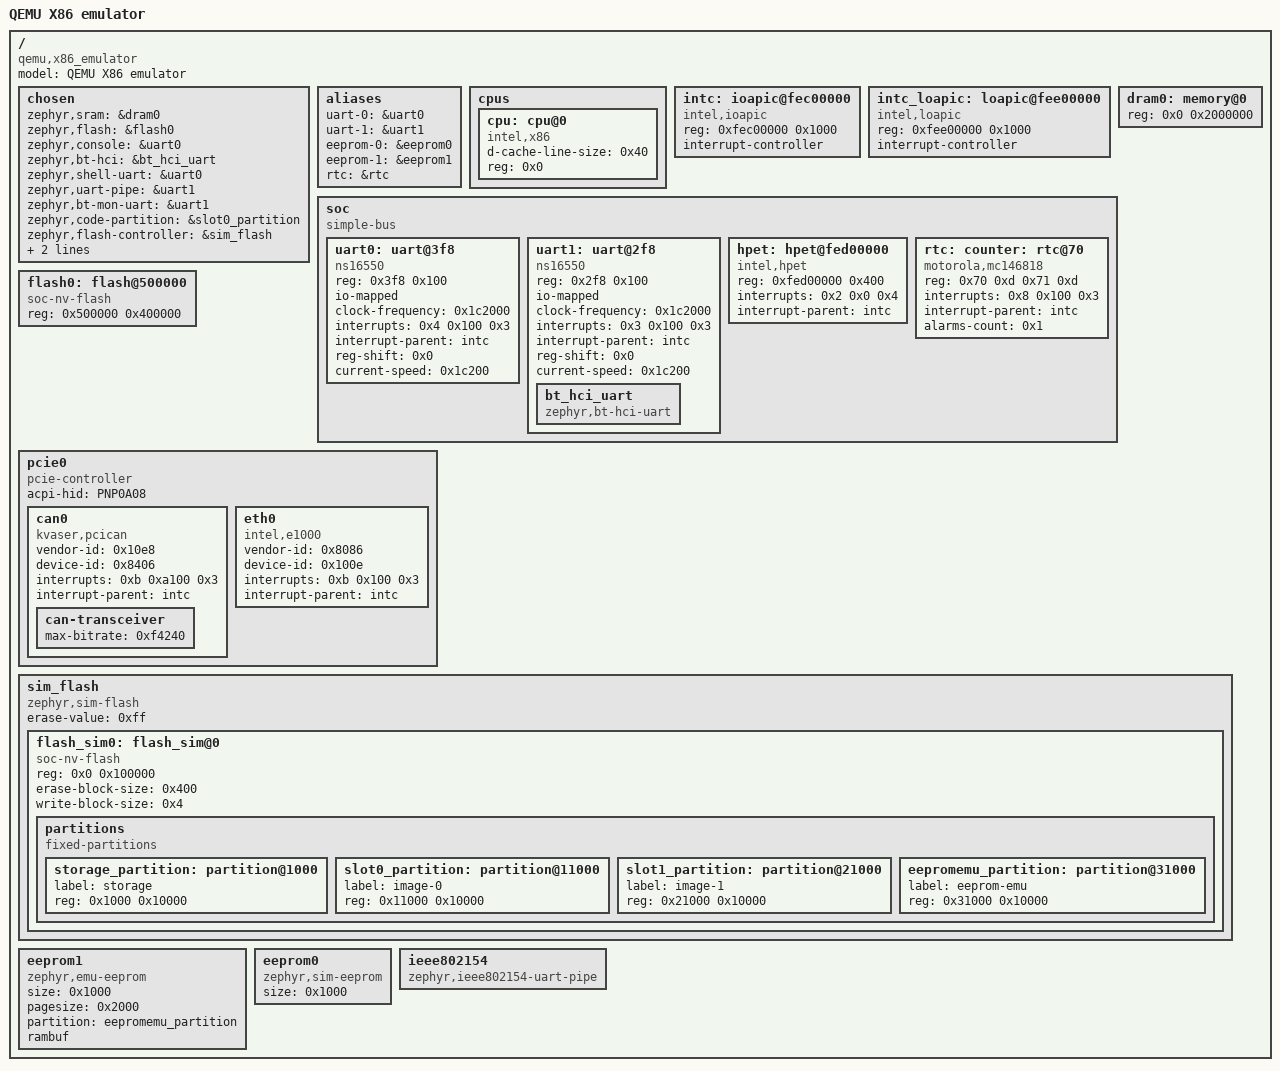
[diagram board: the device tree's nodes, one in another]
/dts-v1/;

/* node '/' defined in deps\zephyr\dts\common\skeleton.dtsi:9 */
/ {
	#address-cells = < 0x1 >;         /* in deps\zephyr\dts\common\skeleton.dtsi:10 */
	#size-cells = < 0x1 >;            /* in deps\zephyr\dts\common\skeleton.dtsi:11 */
	model = "QEMU X86 emulator";      /* in deps\zephyr\boards\qemu\x86\qemu_x86.dts:20 */
	compatible = "qemu,x86_emulator"; /* in deps\zephyr\boards\qemu\x86\qemu_x86.dts:21 */

	/* node '/chosen' defined in deps\zephyr\dts\common\skeleton.dtsi:12 */
	chosen {
		zephyr,sram = &dram0;                     /* in deps\zephyr\boards\qemu\x86\qemu_x86.dts:37 */
		zephyr,flash = &flash0;                   /* in deps\zephyr\boards\qemu\x86\qemu_x86.dts:38 */
		zephyr,console = &uart0;                  /* in deps\zephyr\boards\qemu\x86\qemu_x86.dts:39 */
		zephyr,bt-hci = &bt_hci_uart;             /* in deps\zephyr\boards\qemu\x86\qemu_x86.dts:40 */
		zephyr,shell-uart = &uart0;               /* in deps\zephyr\boards\qemu\x86\qemu_x86.dts:41 */
		zephyr,uart-pipe = &uart1;                /* in deps\zephyr\boards\qemu\x86\qemu_x86.dts:42 */
		zephyr,bt-mon-uart = &uart1;              /* in deps\zephyr\boards\qemu\x86\qemu_x86.dts:43 */
		zephyr,code-partition = &slot0_partition; /* in deps\zephyr\boards\qemu\x86\qemu_x86.dts:44 */
		zephyr,flash-controller = &sim_flash;     /* in deps\zephyr\boards\qemu\x86\qemu_x86.dts:45 */
		zephyr,ieee802154 = &ieee802154;          /* in deps\zephyr\boards\qemu\x86\qemu_x86.dts:46 */
		zephyr,canbus = &can0;                    /* in deps\zephyr\boards\qemu\x86\qemu_x86.dts:47 */
	};

	/* node '/aliases' defined in deps\zephyr\dts\common\skeleton.dtsi:13 */
	aliases {
		uart-0 = &uart0;     /* in deps\zephyr\boards\qemu\x86\qemu_x86.dts:29 */
		uart-1 = &uart1;     /* in deps\zephyr\boards\qemu\x86\qemu_x86.dts:30 */
		eeprom-0 = &eeprom0; /* in deps\zephyr\boards\qemu\x86\qemu_x86.dts:31 */
		eeprom-1 = &eeprom1; /* in deps\zephyr\boards\qemu\x86\qemu_x86.dts:32 */
		rtc = &rtc;          /* in deps\zephyr\boards\qemu\x86\qemu_x86.dts:33 */
	};

	/* node '/cpus' defined in deps\zephyr\dts\x86\intel\atom.dtsi:11 */
	cpus {
		#address-cells = < 0x1 >; /* in deps\zephyr\dts\x86\intel\atom.dtsi:12 */
		#size-cells = < 0x0 >;    /* in deps\zephyr\dts\x86\intel\atom.dtsi:13 */

		/* node '/cpus/cpu@0' defined in deps\zephyr\dts\x86\intel\atom.dtsi:15 */
		cpu: cpu@0 {
			device_type = "cpu";          /* in deps\zephyr\dts\x86\intel\atom.dtsi:16 */
			d-cache-line-size = < 0x40 >; /* in deps\zephyr\dts\x86\intel\atom.dtsi:17 */
			reg = < 0x0 >;                /* in deps\zephyr\dts\x86\intel\atom.dtsi:18 */
			compatible = "intel,x86";     /* in deps\zephyr\boards\qemu\x86\qemu_x86.dts:171 */
		};
	};

	/* node '/ioapic@fec00000' defined in deps\zephyr\dts\x86\intel\atom.dtsi:23 */
	intc: ioapic@fec00000 {
		compatible = "intel,ioapic"; /* in deps\zephyr\dts\x86\intel\atom.dtsi:24 */
		#address-cells = < 0x1 >;    /* in deps\zephyr\dts\x86\intel\atom.dtsi:25 */
		#interrupt-cells = < 0x3 >;  /* in deps\zephyr\dts\x86\intel\atom.dtsi:26 */
		reg = < 0xfec00000 0x1000 >; /* in deps\zephyr\dts\x86\intel\atom.dtsi:27 */
		interrupt-controller;        /* in deps\zephyr\dts\x86\intel\atom.dtsi:28 */
		phandle = < 0x1 >;           /* in deps\zephyr\dts\x86\intel\atom.dtsi:56 */
	};

	/* node '/loapic@fee00000' defined in deps\zephyr\dts\x86\intel\atom.dtsi:31 */
	intc_loapic: loapic@fee00000 {
		compatible = "intel,loapic"; /* in deps\zephyr\dts\x86\intel\atom.dtsi:32 */
		reg = < 0xfee00000 0x1000 >; /* in deps\zephyr\dts\x86\intel\atom.dtsi:33 */
		interrupt-controller;        /* in deps\zephyr\dts\x86\intel\atom.dtsi:34 */
		#interrupt-cells = < 0x3 >;  /* in deps\zephyr\dts\x86\intel\atom.dtsi:35 */
		#address-cells = < 0x1 >;    /* in deps\zephyr\dts\x86\intel\atom.dtsi:36 */
	};

	/* node '/memory@0' defined in deps\zephyr\dts\x86\intel\atom.dtsi:39 */
	dram0: memory@0 {
		device_type = "memory";  /* in deps\zephyr\dts\x86\intel\atom.dtsi:40 */
		reg = < 0x0 0x2000000 >; /* in deps\zephyr\dts\x86\intel\atom.dtsi:41 */
	};

	/* node '/soc' defined in deps\zephyr\dts\x86\intel\atom.dtsi:44 */
	soc {
		#address-cells = < 0x1 >;  /* in deps\zephyr\dts\x86\intel\atom.dtsi:45 */
		#size-cells = < 0x1 >;     /* in deps\zephyr\dts\x86\intel\atom.dtsi:46 */
		compatible = "simple-bus"; /* in deps\zephyr\dts\x86\intel\atom.dtsi:47 */
		ranges;                    /* in deps\zephyr\dts\x86\intel\atom.dtsi:48 */

		/* node '/soc/uart@3f8' defined in deps\zephyr\dts\x86\intel\atom.dtsi:50 */
		uart0: uart@3f8 {
			compatible = "ns16550";         /* in deps\zephyr\dts\x86\intel\atom.dtsi:51 */
			reg = < 0x3f8 0x100 >;          /* in deps\zephyr\dts\x86\intel\atom.dtsi:52 */
			io-mapped;                      /* in deps\zephyr\dts\x86\intel\atom.dtsi:53 */
			clock-frequency = < 0x1c2000 >; /* in deps\zephyr\dts\x86\intel\atom.dtsi:54 */
			interrupts = < 0x4 0x100 0x3 >; /* in deps\zephyr\dts\x86\intel\atom.dtsi:55 */
			interrupt-parent = < &intc >;   /* in deps\zephyr\dts\x86\intel\atom.dtsi:56 */
			reg-shift = < 0x0 >;            /* in deps\zephyr\dts\x86\intel\atom.dtsi:57 */
			status = "okay";                /* in deps\zephyr\boards\qemu\x86\qemu_x86.dts:121 */
			current-speed = < 0x1c200 >;    /* in deps\zephyr\boards\qemu\x86\qemu_x86.dts:122 */
		};

		/* node '/soc/uart@2f8' defined in deps\zephyr\dts\x86\intel\atom.dtsi:61 */
		uart1: uart@2f8 {
			compatible = "ns16550";         /* in deps\zephyr\dts\x86\intel\atom.dtsi:62 */
			reg = < 0x2f8 0x100 >;          /* in deps\zephyr\dts\x86\intel\atom.dtsi:63 */
			io-mapped;                      /* in deps\zephyr\dts\x86\intel\atom.dtsi:64 */
			clock-frequency = < 0x1c2000 >; /* in deps\zephyr\dts\x86\intel\atom.dtsi:65 */
			interrupts = < 0x3 0x100 0x3 >; /* in deps\zephyr\dts\x86\intel\atom.dtsi:66 */
			interrupt-parent = < &intc >;   /* in deps\zephyr\dts\x86\intel\atom.dtsi:67 */
			reg-shift = < 0x0 >;            /* in deps\zephyr\dts\x86\intel\atom.dtsi:68 */
			status = "okay";                /* in deps\zephyr\boards\qemu\x86\qemu_x86.dts:126 */
			current-speed = < 0x1c200 >;    /* in deps\zephyr\boards\qemu\x86\qemu_x86.dts:127 */

			/* node '/soc/uart@2f8/bt_hci_uart' defined in deps\zephyr\boards\qemu\x86\qemu_x86.dts:129 */
			bt_hci_uart: bt_hci_uart {
				compatible = "zephyr,bt-hci-uart"; /* in deps\zephyr\boards\qemu\x86\qemu_x86.dts:130 */
				status = "okay";                   /* in deps\zephyr\boards\qemu\x86\qemu_x86.dts:131 */
			};
		};

		/* node '/soc/hpet@fed00000' defined in deps\zephyr\dts\x86\intel\atom.dtsi:72 */
		hpet: hpet@fed00000 {
			compatible = "intel,hpet";    /* in deps\zephyr\dts\x86\intel\atom.dtsi:73 */
			reg = < 0xfed00000 0x400 >;   /* in deps\zephyr\dts\x86\intel\atom.dtsi:74 */
			interrupts = < 0x2 0x0 0x4 >; /* in deps\zephyr\dts\x86\intel\atom.dtsi:75 */
			interrupt-parent = < &intc >; /* in deps\zephyr\dts\x86\intel\atom.dtsi:76 */
			status = "okay";              /* in deps\zephyr\boards\qemu\x86\qemu_x86.dts:136 */
		};

		/* node '/soc/rtc@70' defined in deps\zephyr\dts\x86\intel\atom.dtsi:81 */
		rtc: counter: rtc@70 {
			compatible = "motorola,mc146818"; /* in deps\zephyr\dts\x86\intel\atom.dtsi:82 */
			reg = < 0x70 0xd 0x71 0xd >;      /* in deps\zephyr\dts\x86\intel\atom.dtsi:83 */
			interrupts = < 0x8 0x100 0x3 >;   /* in deps\zephyr\dts\x86\intel\atom.dtsi:84 */
			interrupt-parent = < &intc >;     /* in deps\zephyr\dts\x86\intel\atom.dtsi:85 */
			alarms-count = < 0x1 >;           /* in deps\zephyr\dts\x86\intel\atom.dtsi:86 */
			status = "okay";                  /* in deps\zephyr\dts\x86\intel\atom.dtsi:88 */
		};
	};

	/* node '/flash@500000' defined in deps\zephyr\boards\qemu\x86\qemu_x86.dts:23 */
	flash0: flash@500000 {
		compatible = "soc-nv-flash"; /* in deps\zephyr\boards\qemu\x86\qemu_x86.dts:24 */
		reg = < 0x500000 0x400000 >; /* in deps\zephyr\boards\qemu\x86\qemu_x86.dts:25 */
	};

	/* node '/pcie0' defined in deps\zephyr\boards\qemu\x86\qemu_x86.dts:50 */
	pcie0: pcie0 {
		#address-cells = < 0x1 >;       /* in deps\zephyr\boards\qemu\x86\qemu_x86.dts:51 */
		#size-cells = < 0x1 >;          /* in deps\zephyr\boards\qemu\x86\qemu_x86.dts:52 */
		compatible = "pcie-controller"; /* in deps\zephyr\boards\qemu\x86\qemu_x86.dts:53 */
		acpi-hid = "PNP0A08";           /* in deps\zephyr\boards\qemu\x86\qemu_x86.dts:54 */
		ranges;                         /* in deps\zephyr\boards\qemu\x86\qemu_x86.dts:55 */

		/* node '/pcie0/can0' defined in deps\zephyr\boards\qemu\x86\qemu_x86.dts:57 */
		can0: can0 {
			compatible = "kvaser,pcican";    /* in deps\zephyr\boards\qemu\x86\qemu_x86.dts:58 */
			status = "okay";                 /* in deps\zephyr\boards\qemu\x86\qemu_x86.dts:59 */
			vendor-id = < 0x10e8 >;          /* in deps\zephyr\boards\qemu\x86\qemu_x86.dts:60 */
			device-id = < 0x8406 >;          /* in deps\zephyr\boards\qemu\x86\qemu_x86.dts:61 */
			interrupts = < 0xb 0xa100 0x3 >; /* in deps\zephyr\boards\qemu\x86\qemu_x86.dts:62 */
			interrupt-parent = < &intc >;    /* in deps\zephyr\boards\qemu\x86\qemu_x86.dts:63 */

			/* node '/pcie0/can0/can-transceiver' defined in deps\zephyr\boards\qemu\x86\qemu_x86.dts:65 */
			can-transceiver {
				max-bitrate = < 0xf4240 >; /* in deps\zephyr\boards\qemu\x86\qemu_x86.dts:66 */
			};
		};

		/* node '/pcie0/eth0' defined in deps\zephyr\boards\qemu\x86\qemu_x86.dts:70 */
		eth0: eth0 {
			compatible = "intel,e1000";     /* in deps\zephyr\boards\qemu\x86\qemu_x86.dts:71 */
			vendor-id = < 0x8086 >;         /* in deps\zephyr\boards\qemu\x86\qemu_x86.dts:73 */
			device-id = < 0x100e >;         /* in deps\zephyr\boards\qemu\x86\qemu_x86.dts:74 */
			interrupts = < 0xb 0x100 0x3 >; /* in deps\zephyr\boards\qemu\x86\qemu_x86.dts:76 */
			interrupt-parent = < &intc >;   /* in deps\zephyr\boards\qemu\x86\qemu_x86.dts:77 */
			status = "okay";                /* in deps\zephyr\boards\qemu\x86\qemu_x86.dts:79 */
		};
	};

	/* node '/sim_flash' defined in deps\zephyr\boards\qemu\x86\qemu_x86.dts:83 */
	sim_flash: sim_flash {
		compatible = "zephyr,sim-flash"; /* in deps\zephyr\boards\qemu\x86\qemu_x86.dts:84 */
		#address-cells = < 0x1 >;        /* in deps\zephyr\boards\qemu\x86\qemu_x86.dts:86 */
		#size-cells = < 0x1 >;           /* in deps\zephyr\boards\qemu\x86\qemu_x86.dts:87 */
		erase-value = < 0xff >;          /* in deps\zephyr\boards\qemu\x86\qemu_x86.dts:88 */

		/* node '/sim_flash/flash_sim@0' defined in deps\zephyr\boards\qemu\x86\qemu_x86.dts:90 */
		flash_sim0: flash_sim@0 {
			compatible = "soc-nv-flash";  /* in deps\zephyr\boards\qemu\x86\qemu_x86.dts:91 */
			reg = < 0x0 0x100000 >;       /* in deps\zephyr\boards\qemu\x86\qemu_x86.dts:92 */
			erase-block-size = < 0x400 >; /* in deps\zephyr\boards\qemu\x86\qemu_x86.dts:94 */
			write-block-size = < 0x4 >;   /* in deps\zephyr\boards\qemu\x86\qemu_x86.dts:95 */

			/* node '/sim_flash/flash_sim@0/partitions' defined in deps\zephyr\boards\qemu\x86\qemu_x86.dts:141 */
			partitions {
				compatible = "fixed-partitions"; /* in deps\zephyr\boards\qemu\x86\qemu_x86.dts:142 */
				#address-cells = < 0x1 >;        /* in deps\zephyr\boards\qemu\x86\qemu_x86.dts:143 */
				#size-cells = < 0x1 >;           /* in deps\zephyr\boards\qemu\x86\qemu_x86.dts:144 */

				/* node '/sim_flash/flash_sim@0/partitions/partition@1000' defined in deps\zephyr\boards\qemu\x86\qemu_x86.dts:150 */
				storage_partition: partition@1000 {
					label = "storage";        /* in deps\zephyr\boards\qemu\x86\qemu_x86.dts:151 */
					reg = < 0x1000 0x10000 >; /* in deps\zephyr\boards\qemu\x86\qemu_x86.dts:152 */
				};

				/* node '/sim_flash/flash_sim@0/partitions/partition@11000' defined in deps\zephyr\boards\qemu\x86\qemu_x86.dts:155 */
				slot0_partition: partition@11000 {
					label = "image-0";         /* in deps\zephyr\boards\qemu\x86\qemu_x86.dts:156 */
					reg = < 0x11000 0x10000 >; /* in deps\zephyr\boards\qemu\x86\qemu_x86.dts:157 */
				};

				/* node '/sim_flash/flash_sim@0/partitions/partition@21000' defined in deps\zephyr\boards\qemu\x86\qemu_x86.dts:159 */
				slot1_partition: partition@21000 {
					label = "image-1";         /* in deps\zephyr\boards\qemu\x86\qemu_x86.dts:160 */
					reg = < 0x21000 0x10000 >; /* in deps\zephyr\boards\qemu\x86\qemu_x86.dts:161 */
				};

				/* node '/sim_flash/flash_sim@0/partitions/partition@31000' defined in deps\zephyr\boards\qemu\x86\qemu_x86.dts:163 */
				eepromemu_partition: partition@31000 {
					label = "eeprom-emu";      /* in deps\zephyr\boards\qemu\x86\qemu_x86.dts:164 */
					reg = < 0x31000 0x10000 >; /* in deps\zephyr\boards\qemu\x86\qemu_x86.dts:165 */
					phandle = < 0x2 >;         /* in deps\zephyr\boards\qemu\x86\qemu_x86.dts:104 */
				};
			};
		};
	};

	/* node '/eeprom1' defined in deps\zephyr\boards\qemu\x86\qemu_x86.dts:99 */
	eeprom1: eeprom1 {
		status = "okay";                      /* in deps\zephyr\boards\qemu\x86\qemu_x86.dts:100 */
		compatible = "zephyr,emu-eeprom";     /* in deps\zephyr\boards\qemu\x86\qemu_x86.dts:101 */
		size = < 0x1000 >;                    /* in deps\zephyr\boards\qemu\x86\qemu_x86.dts:102 */
		pagesize = < 0x2000 >;                /* in deps\zephyr\boards\qemu\x86\qemu_x86.dts:103 */
		partition = < &eepromemu_partition >; /* in deps\zephyr\boards\qemu\x86\qemu_x86.dts:104 */
		rambuf;                               /* in deps\zephyr\boards\qemu\x86\qemu_x86.dts:105 */
	};

	/* node '/eeprom0' defined in deps\zephyr\boards\qemu\x86\qemu_x86.dts:108 */
	eeprom0: eeprom0 {
		status = "okay";                  /* in deps\zephyr\boards\qemu\x86\qemu_x86.dts:109 */
		compatible = "zephyr,sim-eeprom"; /* in deps\zephyr\boards\qemu\x86\qemu_x86.dts:110 */
		size = < 0x1000 >;                /* in deps\zephyr\boards\qemu\x86\qemu_x86.dts:111 */
	};

	/* node '/ieee802154' defined in deps\zephyr\boards\qemu\x86\qemu_x86.dts:114 */
	ieee802154: ieee802154 {
		compatible = "zephyr,ieee802154-uart-pipe"; /* in deps\zephyr\boards\qemu\x86\qemu_x86.dts:115 */
	};
};
